# f29h85x_hsm_pke_regs register map
Vendor: Texas Instruments
Peripheral module from a debugger description file (folder HSM).
Registers are 32-bit, read-only, no defined reset value unless marked. A register's access mark holds for its fields unless they carry their own. Offsets are as the file gives them; lines under a group give offsets from that group; [hi:lo] are bit positions; {n}, {i} and the like mark numbered series; 'fields as' and 'values as' point back to an identical list; <NAME> marks a mode.

## HSM_PKE — HSM PKE Registers
0x00 PKE_RESET_CTRL rw
  [20] PKEFLUSH
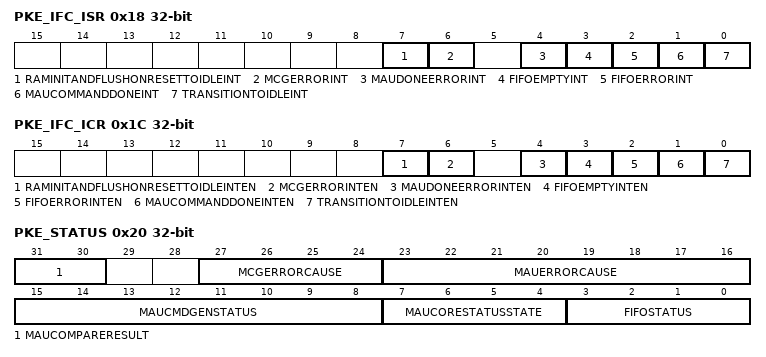
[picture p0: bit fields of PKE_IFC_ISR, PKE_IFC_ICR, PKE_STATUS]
0x18 PKE_IFC_ISR rw
  [7] RAMINITANDFLUSHONRESETTOIDLEINT, [6] MCGERRORINT, [4] MAUDONEERRORINT, [3] FIFOEMPTYINT, [2] FIFOERRORINT, [1] MAUCOMMANDDONEINT, [0] TRANSITIONTOIDLEINT
0x1C PKE_IFC_ICR rw
  [7] RAMINITANDFLUSHONRESETTOIDLEINTEN, [6] MCGERRORINTEN, [4] MAUDONEERRORINTEN, [3] FIFOEMPTYINTEN, [2] FIFOERRORINTEN, [1] MAUCOMMANDDONEINTEN, [0] TRANSITIONTOIDLEINTEN
0x20 PKE_STATUS
  [31:30] MAUCOMPARERESULT, [27:24] MCGERRORCAUSE, [23:16] MAUERRORCAUSE, [15:8] MAUCMDGENSTATUS, [7:4] MAUCORESTATUSSTATE, [3:0] FIFOSTATUS
0x30 PKE_SCRATCH rw
  [31:0] MAUIFCSCRATCH
0x34 MAU_MIN_LEN
  [31:0] MAUMINLEN
0x38 MAU_MAX_LEN
  [31:0] MAUMAXLEN
0x3C PKE_VERSION
  [31:0] PKEVERSION
{0x40+4i} MCG_COMMANDS_ENABLED_{i} (i=0..3)
  [31:0] MCGCOMMANDSENABLED
{0x50+4i} PKE_PRNG_SEED_{i} rw (i=0..3)
  [31:0] PKEPRNGSEED_{i}
0x60 PKE_WORD_SIZE
  [31:0] PKEWORDSIZE
0x64 PKE_CURVES_IN_ROM_0
  [31:0] PKECURVESINROM
0x68 PKE_CURVES_IN_ROM_1
  [31:0] PKECURVESINROM
0x6C PKE_SPECIAL_PRIMES
  [31:0] PKESPECIALPRIMES
0x70 PKE_SRAM_ADDR_MIN
  [31:0] PKESRAMADDRMIN
0x74 PKE_SRAM_ADDR_MAX
  [31:0] PKESRAMADDRMAX
0x80 MAU_COMMAND rw
  [31:0] MAUCOMMAND
0x88 MAU_MCG_COMMAND rw
  [31:0] MAUCOMMANDCMDGEN
{0x2000+4i} CONTEXT_MEM[{i}] (i=0..1023) rw
  [31:0] CONTEXT_WORD
